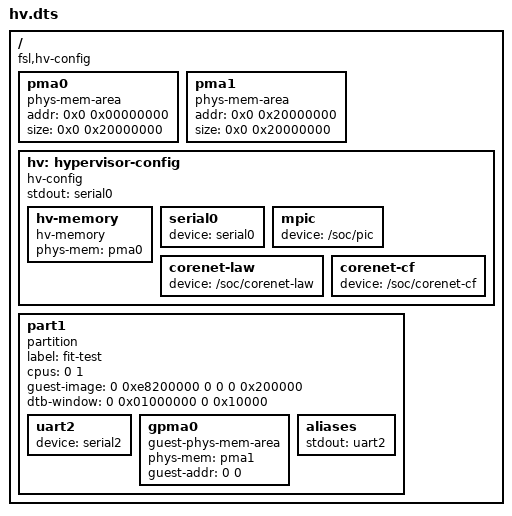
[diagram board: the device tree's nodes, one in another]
/dts-v1/;

/ {
	compatible = "fsl,hv-config";

	// =====================================================
	// Physical Memory Areas
	// =====================================================
	pma0:pma0 {
		compatible = "phys-mem-area";
		addr = <0x0 0x00000000>;
		size = <0x0 0x20000000>;  // 512MB
	};
	pma1:pma1 {
		compatible = "phys-mem-area";
		addr = <0x0 0x20000000>;
		size = <0x0 0x20000000>;  // 512MB
	};

	// =====================================================
	// Hypervisor Config
	// =====================================================
	hv:hypervisor-config {
		compatible = "hv-config";
		stdout = <&serial0>;

		hv-memory {
			compatible = "hv-memory";
			phys-mem = <&pma0>;
		};

		serial0:serial0 {
			device = "serial0";
		};

		mpic {
			device = "/soc/pic";
		};

		corenet-law {
			device = "/soc/corenet-law";
		};

		corenet-cf {
			device = "/soc/corenet-cf";
		};
	};

	// =====================================================
	// Partition 1
	// =====================================================
	part1 {
		compatible = "partition";
		label = "fit-test";
		cpus = <0 1>;
		guest-image = <0 0xe8200000 0 0 0 0x200000>;
		dtb-window = <0 0x01000000 0 0x10000>;

		uart2: uart2 {
			device = "serial2";
		};

		gpma0 {
			compatible = "guest-phys-mem-area";
			phys-mem = <&pma1>;
			guest-addr = <0 0>;
		};

		aliases {
			stdout = <&uart2>;
		};

	};
};
